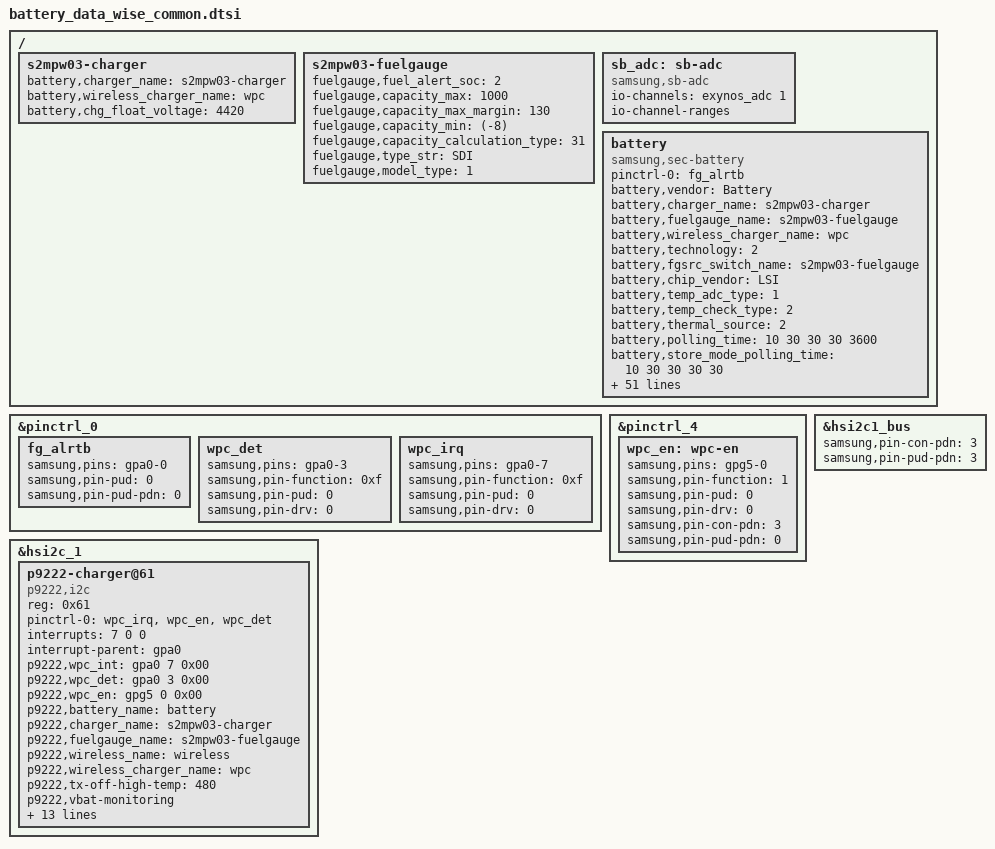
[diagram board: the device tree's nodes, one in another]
/*
 * SAMSUNG EXYNOS5515 board device tree source
 *
 * Copyright (c) 2021 Samsung Electronics Co., Ltd.
 *		http://www.samsung.com
 *
 * This program is free software; you can redistribute it and/or modify
 * it under the terms of the GNU General Public License version 2 as
 * published by the Free Software Foundation.
 */

#include "battery_macros.dtsi"

&pinctrl_0 {
	fg_alrtb: fg_alrtb {
		/* init & sleep state = PIN_PULL_NONE(0) */
		samsung,pins = "gpa0-0";
		samsung,pin-pud = <0>;
		samsung,pin-pud-pdn = <0>;
	};

	wpc_det: wpc_det {
		samsung,pins = "gpa0-3";
		samsung,pin-function = <0xf>;
		samsung,pin-pud = <0>;
		samsung,pin-drv = <0>;
	};

	wpc_irq: wpc_irq {
		samsung,pins = "gpa0-7";
		samsung,pin-function = <0xf>;
		samsung,pin-pud = <0>;
		samsung,pin-drv = <0>;
	};
};

&pinctrl_4 {
	wpc_en: wpc-en {
		samsung,pins = "gpg5-0";
		samsung,pin-function = <1>;
		samsung,pin-pud = <0>;
		samsung,pin-drv = <0>;
		samsung,pin-con-pdn = <3>;
		samsung,pin-pud-pdn = <0>;
	};
};

&hsi2c1_bus {
	samsung,pin-con-pdn = <3>;
	samsung,pin-pud-pdn = <3>;
};

&hsi2c_1 {
	status = "okay";

	p9222-charger@61{
		compatible = "p9222,i2c";
		reg = <0x61>;
		pinctrl-names = "default";
		pinctrl-0 = <&wpc_irq &wpc_en &wpc_det>;
		interrupts = <7 0 0>;
		interrupt-parent = <&gpa0>;
		p9222,wpc_int = <&gpa0 7 0x00>;
		p9222,wpc_det = <&gpa0 3 0x00>;
		p9222,wpc_en = <&gpg5 0 0x00>;

		p9222,battery_name = "battery";
		p9222,charger_name = "s2mpw03-charger";
		p9222,fuelgauge_name = "s2mpw03-fuelgauge";
		p9222,wireless_name = "wireless";
		p9222,wireless_charger_name = "wpc";

		p9222,tx-off-high-temp = <480>;

		p9222,vbat-monitoring;
		p9222,ping_duration = <200>;
		p9222,ps_wpc_en_toggle_time = <1050>;
		p9222,cc_cv_threshold = <880>;
		p9222,rx_id = <0x56>;
		p9222,enable_batt_mode_headroom_margin = <0>;
		p9222,boot_ap_mode = <0x6>;
		p9222,low_vout_level = <4500>;
		p9222,ex_low_vout_level = <0x74 4440>;
		p9222,charger_type = <
			/* tx_id, supp_phm, pad_type, cc, cv, half_bridge, phm_time, cv_thr, half_thr */
			0x56 0x1 0x0 0x02 0x11 0x06 1050 880 950 /* Pulse Grobal PAD */
			0x57 0x1 0x0 0x10 0x11 0x06 1050 880 950 /* Pulse Vietnam PAD */
			0x58 0x1 0x0 0x02 0x11 0x06 900 850 920	/* Reserved */
			0x59 0x1 0x0 0x02 0x11 0x06 900 880 950	/* Reserved */
			0x5A 0x1 0x0 0x02 0x11 0x06 900 880 950	/* Reserved */
			0x5B 0x1 0x0 0x02 0x11 0x06 900 880 950	/* Reserved */
			0x5C 0x1 0x0 0x02 0x11 0x06 900 880 950	/* Reserved */
			0x5D 0x1 0x0 0x02 0x11 0x06 900 880 950	/* Reserved */
			0x5E 0x1 0x0 0x02 0x11 0x06 900 880 950	/* Reserved */
			0x5F 0x1 0x0 0x02 0x11 0x06 900 880 950	/* Reserved */

			0x70 0x1 0x2 0x03 0x07 0x08 510 880 950	/* EP-N6100 */
			0x71 0x1 0x2 0x03 0x07 0x08 510 880 950	/* EP-P3100 */
			0x72 0x1 0x1 0x10 0x11 0x06 510 880 950	/* IDT FW TX mode */
			0x73 0x1 0x2 0x03 0x07 0x08 510 880 950	/* P5200 Gear mode */
			0x74 0x1 0x2 0x05 0x09 0x01 510 880 950	/* U1200 Gear mode */
			0x75 0x1 0x2 0x02 0x11 0x06 1050 880 950 /* P6300, P4300 */
			0x76 0x1 0x4 0x02 0x11 0x06 1050 880 950 /* P5400 */
			0x77 0x1 0x4 0x02 0x11 0x06 1050 880 950 /* SMAPP */
			0x78 0x1 0x2 0x03 0x07 0x08 1050 880 950 /* Reserved */
			0x79 0x1 0x2 0x03 0x07 0x08 1050 880 950 /* Reserved */
			0x7A 0x1 0x2 0x03 0x07 0x08 1050 880 950 /* Reserved */
			0x7B 0x1 0x2 0x03 0x07 0x08 1050 880 950 /* Reserved */
			0x7C 0x1 0x2 0x03 0x07 0x08 1050 880 950 /* Reserved */
			0x7D 0x1 0x2 0x03 0x07 0x08 1050 880 950 /* Reserved */
			0x7E 0x0 0x3 0x02 0x11 0x06 1050 880 950 /* Illegal PAD(KT) */
			0x7F 0x1 0x2 0x03 0x07 0x08 1050 880 950 /* Reserved */

			0x80 0x1 0x1 0x10 0x11 0x06 510 880 950	/* B0 power sharing charge */
			0x81 0x1 0x1 0x10 0x11 0x06 510 880 950	/* B1 power sharing charge */
			0x82 0x1 0x1 0x10 0x11 0x06 510 880 950	/* B2 power sharing charge */
			0x83 0x1 0x1 0x10 0x11 0x06 510 880 950	/* Reserved */
			0x84 0x1 0x1 0x10 0x11 0x06 510 880 950	/* Reserved */
			0x85 0x1 0x1 0x10 0x11 0x06 510 880 950	/* Reserved */
			0x86 0x1 0x1 0x10 0x11 0x06 510 880 950	/* Reserved */
			0x87 0x1 0x1 0x10 0x11 0x06 510 880 950	/* Reserved */
			0x88 0x1 0x1 0x10 0x11 0x06 510 880 950	/* Reserved */
			0x89 0x1 0x1 0x10 0x11 0x06 510 880 950	/* Reserved */
			0x8A 0x1 0x1 0x10 0x11 0x06 510 880 950	/* Reserved */
			0x8B 0x1 0x1 0x10 0x11 0x06 510 880 950	/* Reserved */
			0x8C 0x1 0x1 0x10 0x11 0x06 510 880 950	/* Reserved */
			0x8D 0x1 0x1 0x10 0x11 0x06 510 880 950	/* Reserved */
			0x8E 0x1 0x1 0x10 0x11 0x06 510 880 950	/* Reserved */
			0x8F 0x1 0x1 0x10 0x11 0x06 510 880 950	/* Reserved */
			>;
		p9222,op_freq = <
			/* freq, strength */
			4500	100
			0	0
			>;
		p9222,ap_mode_table = <
			/* ap_mode, vout, vrect, batt_mode_margin */
			0x00	5000	6000	0
			0x01	5000	5350	0
			0x02	4200	4300	300
			0x03	4300	4400	300
			0x04	4400	4500	300
			0x05	4500	4600	300
			0x06	4800	5160	0
			0x07	4800	5280	0
			0x08	4900	5260	0
			0x09	4900	5380	0
			0x0A	4900	5460	0
			0x0B	4900	5550	0
			0x0C	5100	5500	0
			0x0D	5100	5600	0
			0x0E	5100	5700	0
			0x0F	5100	5800	0
			0x10	4600	4700	0
			0x11	4700	4800	0
			>;
	};
};

/ {
	fragment@battery {
		target-path = "/";
		__overlay__ {
			s2mpw03-charger {
				battery,charger_name = "s2mpw03-charger";
				battery,wireless_charger_name = "wpc";
				battery,chg_float_voltage = <4420>;
			};

			s2mpw03-fuelgauge {
				fuelgauge,fuel_alert_soc = <2>;
				fuelgauge,capacity_max = <1000>;
				fuelgauge,capacity_max_margin = <130>;
				fuelgauge,capacity_min = <(-8)>;
				fuelgauge,capacity_calculation_type = <31>;
				fuelgauge,type_str = "SDI";
				fuelgauge,model_type = <1>;
			};

			sb_adc: sb-adc {
				compatible = "samsung,sb-adc";
				status = "okay";

				io-channels = <&exynos_adc 1>;
				io-channel-names = "batt_temp";
				io-channel-ranges;
			};

			battery {
				status = "okay";
				compatible = "samsung,sec-battery";

				pinctrl-names = "default";
				pinctrl-0 = <&fg_alrtb>;
				/* battery,irq_gpio = <&gpa1 6 0>; */

				battery,vendor = "Battery";
				battery,charger_name = "s2mpw03-charger";
				battery,fuelgauge_name = "s2mpw03-fuelgauge";
				battery,wireless_charger_name = "wpc";
				battery,technology = <2>; /* POWER_SUPPLY_TECHNOLOGY_LION */
				battery,fgsrc_switch_name = "s2mpw03-fuelgauge"; /* Fuelgauge voltage source */

				battery,chip_vendor = "LSI";
				battery,temp_adc_type = <1>; /* SEC_BATTERY_ADC_TYPE_AP */
				battery,temp_check_type = <2>; /* SEC_BATTERY_TEMP_CHECK_TEMP */
				battery,thermal_source = <2>; /* SEC_BATTERY_THERMAL_SOURCE_ADC */

				battery,polling_time = <10 30 30 30 3600>;
				battery,store_mode_polling_time = <10 30 30 30 30>;

				battery,adc_check_count = <6>;

				battery,cable_check_type = <16>; /* SEC_BATTERY_CABLE_CHECK_CHGINT */
				battery,cable_source_type = <1>; /* SEC_BATTERY_CABLE_SOURCE_EXTERNAL */
				battery,polling_type = <1>; /* SEC_BATTERY_MONITOR_ALARM */
				battery,monitor_initial_count = <0>;

				battery,battery_check_type = <0>; /* SEC_BATTERY_CHECK_NONE */
				battery,check_count = <0>;
				battery,check_adc_max = <1440>;
				battery,check_adc_min = <0>;

				battery,ovp_uvlo_check_type = <3>; /* SEC_BATTERY_OVP_UVLO_CHGPOLLING */

				battery,temp_check_count = <1>;

				battery,full_check_type = <7>; /* SEC_BATTERY_FULLCHARGED_CHGPSY */
				battery,full_check_type_2nd = <3>; /* SEC_BATTERY_FULLCHARGED_TIME */
				battery,full_check_count = <1>;
				battery,swell_full_check_count = <50>;
				battery,chg_gpio_full_check = <0>;
				battery,chg_polarity_full_check = <1>;

				/* SEC_BATTERY_FULL_CONDITION_NOTIMEFULL | SEC_BATTERY_FULL_CONDITION_NOSLEEPINFULL | SEC_BATTERY_FULL_CONDITION_SOC */
				battery,full_condition_type = <7>;
				battery,full_condition_soc = <93>;
				battery,full_condition_vcell = <4320>;

				battery,recharge_check_count = <2>;
				battery,recharge_condition_type = <4>; /* SEC_BATTERY_RECHARGE_CONDITION_VCELL */
				battery,recharge_condition_soc = <98>;
				battery,recharge_condition_vcell = <4320>;

				battery,chg_float_voltage = <4420>;

				battery,wire_warm_overheat_thresh = <450>;
				battery,wire_normal_warm_thresh = <420>;
				battery,wire_cool1_normal_thresh = <150>;
				battery,wire_cool2_cool1_thresh = <150>;
				battery,wire_cool3_cool2_thresh = <50>;
				battery,wire_cold_cool3_thresh = <0>;

				battery,wireless_prevent_overheat_thresh = <500>;
				battery,wireless_warm_overheat_thresh = <450>;
				battery,wireless_normal_warm_thresh = <420>;
				battery,wireless_cool1_normal_thresh = <150>;
				battery,wireless_cool2_cool1_thresh = <150>;
				battery,wireless_cool3_cool2_thresh = <50>;
				battery,wireless_cold_cool3_thresh = <0>;

				battery,high_temp_float = <4270>;
				battery,swelling_high_rechg_voltage = <4120>;
				battery,low_temp_float = <4420>;
				battery,swelling_low_rechg_voltage = <4270>;

				battery,enable_sysovlo_irq;

				battery,single_charger_path;
				battery,expired_time = <12600>;
				battery,recharging_expired_time = <7500>;

				battery,cisd_max_voltage_thr = <4450>; /* battery ovp detection voltage */

				battery,cisd_alg_index = <7>;

				battery,boot_charge_current = <175>;

				/* cycle, chg_float_voltage, recharge_condition_vcell, full_condition_vcell, full_condition_soc */
				battery,age_data = <
						0 4420 4320 4320 93		/*4.420*/
						300 4400 4300 4300 92	/*4.400*/
						400 4380 4280 4280 91	/*4.380*/
						700 4360 4260 4260 90	/*4.360*/
						1000 4310 4210 4210 89	/*4.310*/
						>;
			};
		};
	};
};
